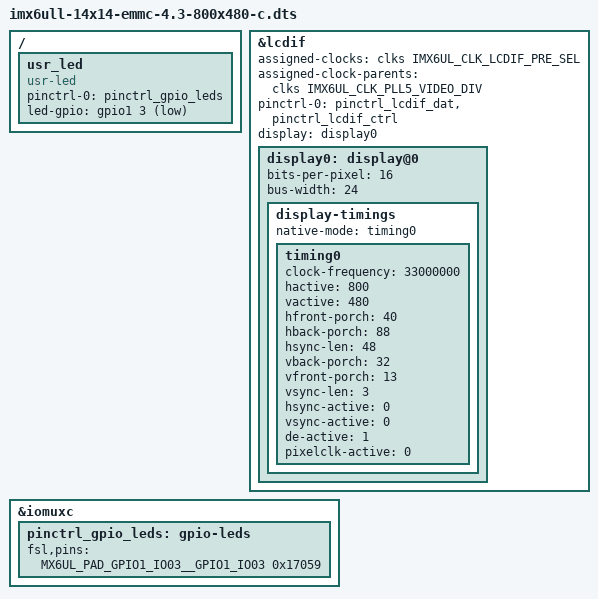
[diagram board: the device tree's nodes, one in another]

#include "imx6ull-14x14-usr-emmc.dts"

/ {
	usr_led {
		compatible = "usr-led";
		pinctrl-0 = <&pinctrl_gpio_leds>;
		led-gpio = <&gpio1 3 GPIO_ACTIVE_LOW>;
		status = "okay";
	};
};

&lcdif {
	assigned-clocks = <&clks IMX6UL_CLK_LCDIF_PRE_SEL>;
	assigned-clock-parents = <&clks IMX6UL_CLK_PLL5_VIDEO_DIV>;
	pinctrl-names = "default";
	pinctrl-0 = <&pinctrl_lcdif_dat
		     &pinctrl_lcdif_ctrl>;
	display = <&display0>;
	status = "okay";

	display0: display@0 {
		bits-per-pixel = <16>;
		bus-width = <24>;

		display-timings {
			native-mode = <&timing0>;
            
			timing0: timing0 {
                clock-frequency = <33000000>;
                hactive = <800>;
                vactive = <480>;
                hfront-porch = <40>;
                hback-porch = <88>;
                hsync-len = <48>;
                vback-porch = <32>;
                vfront-porch = <13>;
                vsync-len = <3>;

                hsync-active = <0>;
                vsync-active = <0>;
                de-active = <1>;
                pixelclk-active = <0>;
			};
		};
	};
};

&iomuxc {
    pinctrl_gpio_leds: gpio-leds {
        fsl,pins = <
            MX6UL_PAD_GPIO1_IO03__GPIO1_IO03	0x17059
        >;
    };
};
